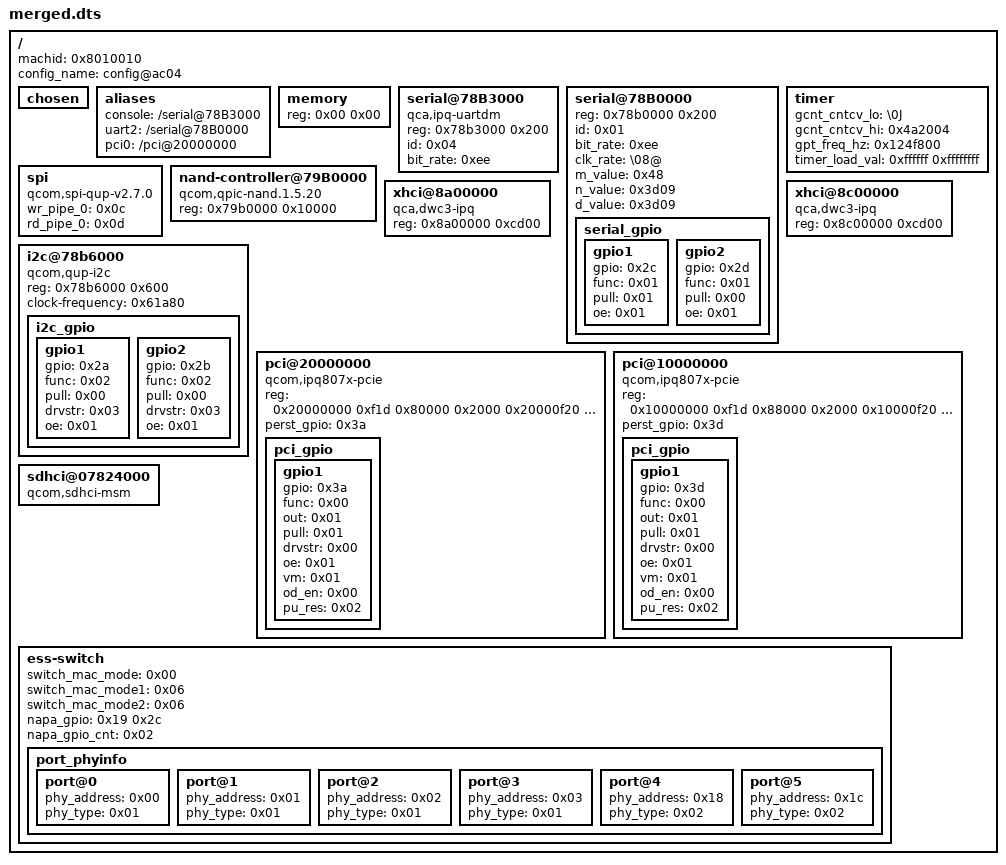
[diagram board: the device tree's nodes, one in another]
/dts-v1/;

/ {
	#address-cells = <0x01>;
	#size-cells = <0x01>;
	machid = <0x8010010>;
	config_name = "config@ac04";

	chosen {
	};

	aliases {
		console = "/serial@78B3000";
		uart2 = "/serial@78B0000";
		pci0 = "/pci@20000000";
	};

	memory {
		device_type = "memory";
		reg = <0x00 0x00>;
	};

	serial@78B3000 {
		compatible = "qca,ipq-uartdm";
		reg = <0x78b3000 0x200>;
		id = <0x04>;
		bit_rate = <0xee>;
	};

	serial@78B0000 {
		reg = <0x78b0000 0x200>;
		id = <0x01>;
		bit_rate = <0xee>;
		clk_rate = "\08@";
		m_value = <0x48>;
		n_value = <0x3d09>;
		d_value = <0x3d09>;

		serial_gpio {

			gpio1 {
				gpio = <0x2c>;
				func = <0x01>;
				pull = <0x01>;
				oe = <0x01>;
			};

			gpio2 {
				gpio = <0x2d>;
				func = <0x01>;
				pull = <0x00>;
				oe = <0x01>;
			};
		};
	};

	timer {
		gcnt_cntcv_lo = "\0J ";
		gcnt_cntcv_hi = <0x4a2004>;
		gpt_freq_hz = <0x124f800>;
		timer_load_val = <0xffffff 0xffffffff>;
	};

	spi {
		status = "ok";
		compatible = "qcom,spi-qup-v2.7.0";
		wr_pipe_0 = <0x0c>;
		rd_pipe_0 = <0x0d>;
	};

	nand-controller@79B0000 {
		#address-cells = <0x01>;
		#size-cells = <0x00>;
		compatible = "qcom,qpic-nand.1.5.20";
		reg = <0x79b0000 0x10000>;
	};

	xhci@8a00000 {
		compatible = "qca,dwc3-ipq";
		#address-cells = <0x01>;
		#size-cells = <0x01>;
		reg = <0x8a00000 0xcd00>;
	};

	xhci@8c00000 {
		compatible = "qca,dwc3-ipq";
		#address-cells = <0x01>;
		#size-cells = <0x01>;
		reg = <0x8c00000 0xcd00>;
	};

	i2c@78b6000 {
		compatible = "qcom,qup-i2c";
		#address-cells = <0x01>;
		#size-cells = <0x00>;
		reg = <0x78b6000 0x600>;
		clock-frequency = <0x61a80>;

		i2c_gpio {

			gpio1 {
				gpio = <0x2a>;
				func = <0x02>;
				pull = <0x00>;
				drvstr = <0x03>;
				oe = <0x01>;
			};

			gpio2 {
				gpio = <0x2b>;
				func = <0x02>;
				pull = <0x00>;
				drvstr = <0x03>;
				oe = <0x01>;
			};
		};
	};

	pci@20000000 {
		compatible = "qcom,ipq807x-pcie";
		#address-cells = <0x01>;
		#size-cells = <0x01>;
		reg = <0x20000000 0xf1d 0x80000 0x2000 0x20000f20 0xa8 0x20001000 0x1000 0x20300000 0xd00000 0x20100000 0x100000 0x1875004 0x40 0x86000 0x1000 0x84000 0x1000>;
		reg-names = "pci_dbi\0parf\0elbi\0dm_iatu\0axi_bars\0axi_conf\0pci_rst\0pci_phy_gen2\0pci_phy_gen3";
		perst_gpio = <0x3a>;

		pci_gpio {

			gpio1 {
				gpio = <0x3a>;
				func = <0x00>;
				out = <0x01>;
				pull = <0x01>;
				drvstr = <0x00>;
				oe = <0x01>;
				vm = <0x01>;
				od_en = <0x00>;
				pu_res = <0x02>;
			};
		};
	};

	pci@10000000 {
		compatible = "qcom,ipq807x-pcie";
		#address-cells = <0x01>;
		#size-cells = <0x01>;
		reg = <0x10000000 0xf1d 0x88000 0x2000 0x10000f20 0xa8 0x10300000 0xd00000 0x10100000 0x100000 0x1876004 0x40 0x8e000 0x1000>;
		reg-names = "pci_dbi\0parf\0elbi\0axi_bars\0axi_conf\0pci_rst\0pci_phy";
		perst_gpio = <0x3d>;

		pci_gpio {

			gpio1 {
				gpio = <0x3d>;
				func = <0x00>;
				out = <0x01>;
				pull = <0x01>;
				drvstr = <0x00>;
				oe = <0x01>;
				vm = <0x01>;
				od_en = <0x00>;
				pu_res = <0x02>;
			};
		};
	};

	sdhci@07824000 {
		compatible = "qcom,sdhci-msm";
	};

	ess-switch {
		switch_mac_mode = <0x00>;
		switch_mac_mode1 = <0x06>;
		switch_mac_mode2 = <0x06>;
		napa_gpio = <0x19 0x2c>;
		napa_gpio_cnt = <0x02>;

		port_phyinfo {

			port@0 {
				phy_address = <0x00>;
				phy_type = <0x01>;
			};

			port@1 {
				phy_address = <0x01>;
				phy_type = <0x01>;
			};

			port@2 {
				phy_address = <0x02>;
				phy_type = <0x01>;
			};

			port@3 {
				phy_address = <0x03>;
				phy_type = <0x01>;
			};

			port@4 {
				phy_address = <0x18>;
				phy_type = <0x02>;
			};

			port@5 {
				phy_address = <0x1c>;
				phy_type = <0x02>;
			};
		};
	};
};
